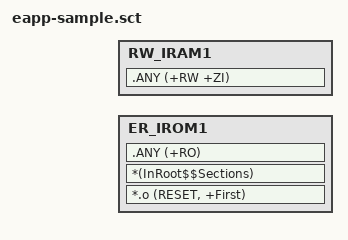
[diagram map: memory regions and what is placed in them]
#! armcc -E
; due to a bug in linker (in some older versions), you may need to put the whole path ... thus change it by hand
;#include "D:\#inhere\sdl\embedded\arm\embody\body\embenv\envcom\eEmemorymap.h"
#include "..\..\..\envcom\eEmemorymap.h"


LR_IROM1 EENV_MEMMAP_EAPPLICATION_ROMADDR EENV_MEMMAP_EAPPLICATION_ROMSIZE  {    ; load region size_region
  ER_IROM1 EENV_MEMMAP_EAPPLICATION_ROMADDR EENV_MEMMAP_EAPPLICATION_ROMSIZE  {  ; load address = execution address
   *.o (RESET, +First)
   *(InRoot$$Sections)
   .ANY (+RO)
  }
  RW_IRAM1 EENV_MEMMAP_EAPPLICATION_RAMADDR EENV_MEMMAP_EAPPLICATION_RAMSIZE  {  ; RW data
   .ANY (+RW +ZI)
  }
} 




